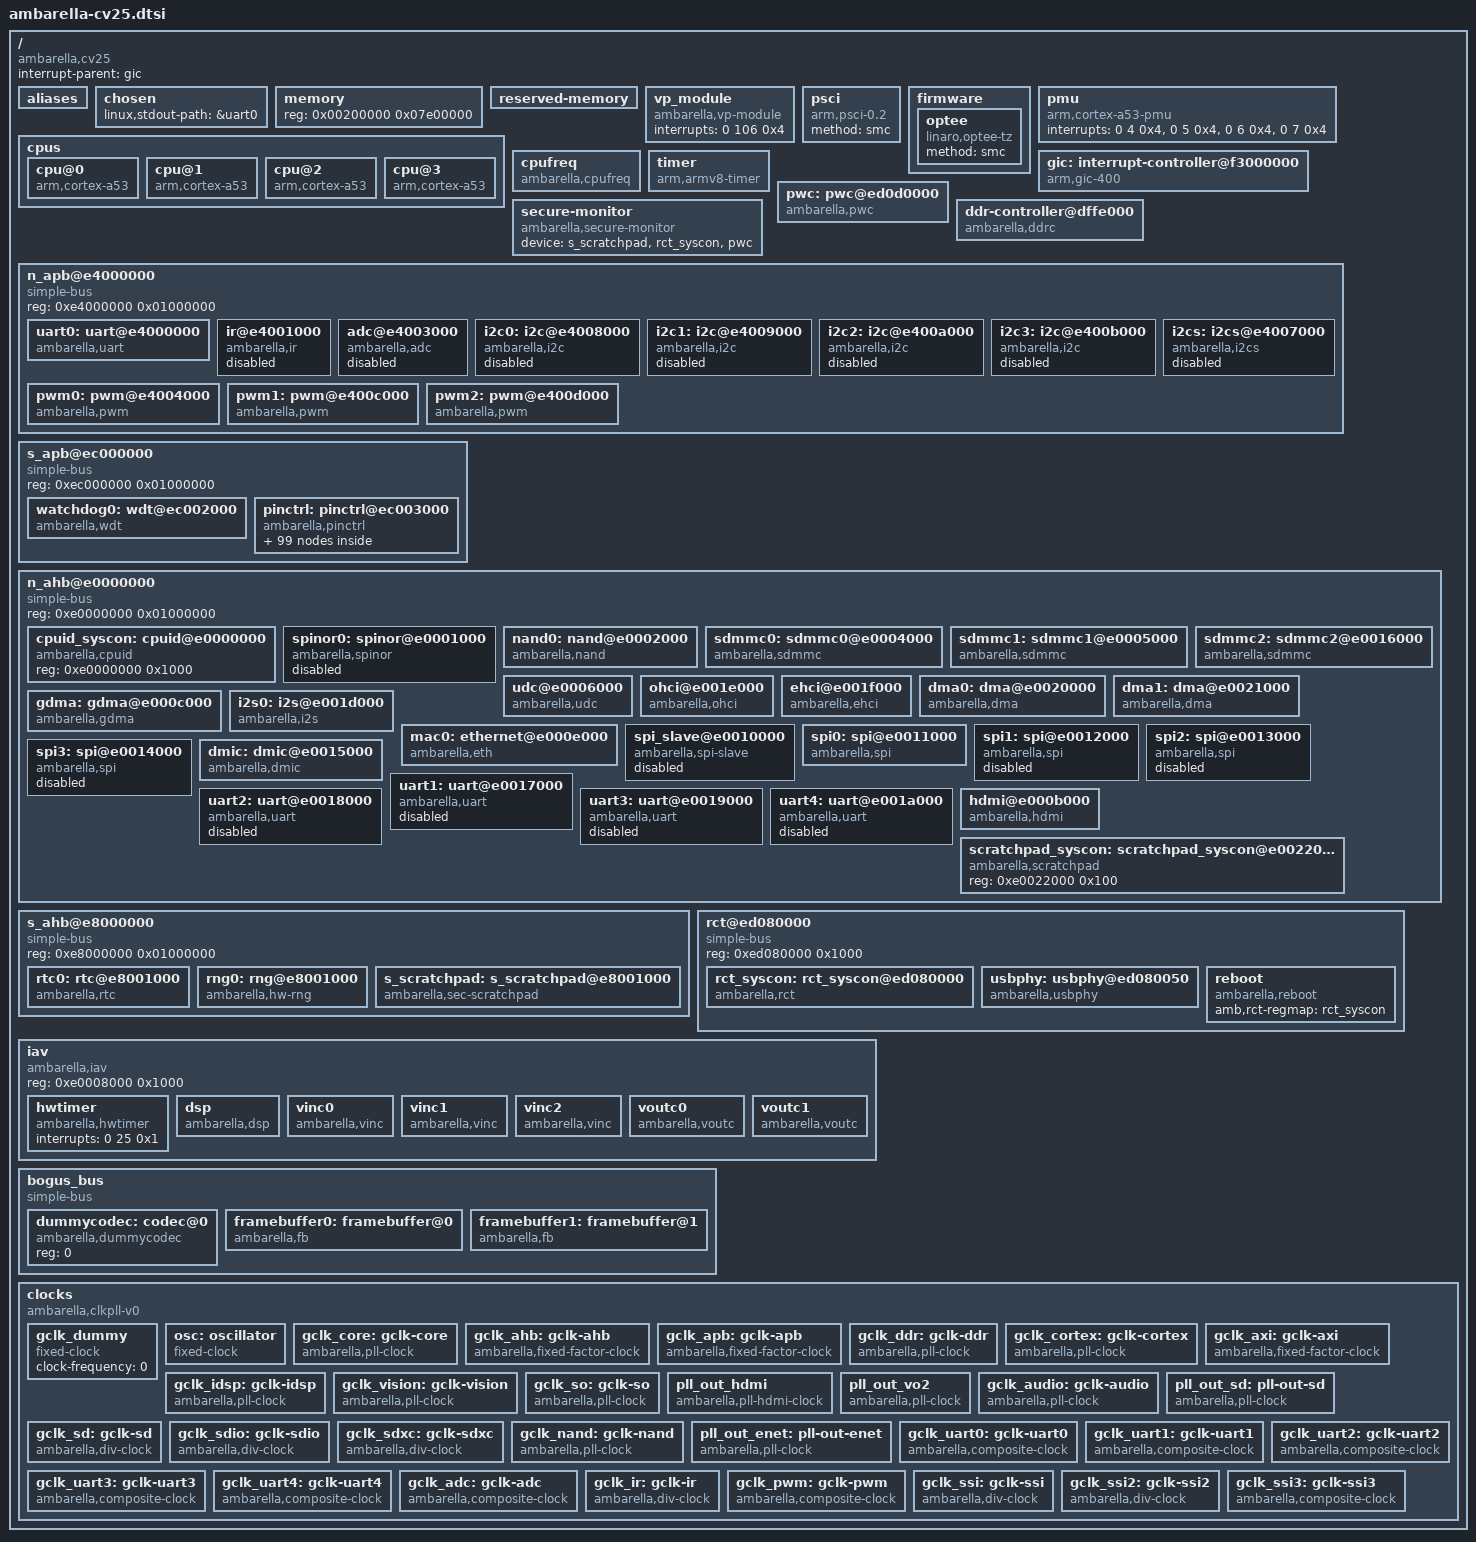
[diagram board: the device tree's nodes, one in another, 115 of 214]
/*
 * Copyright (C) 2013 Ambarella,Inc. - http://www.ambarella.com/
 * Author: Cao Rongrong <rrcao@ambarella.com>
 *
 * This program is free software; you can redistribute it and/or modify
 * it under the terms of the GNU General Public License version 2 as
 * published by the Free Software Foundation.
 */

/ {
	compatible = "ambarella,cv25";
	interrupt-parent = <&gic>;
	#address-cells = <1>;
	#size-cells = <1>;

	aliases {
		serial0 = &uart0;
		serial1 = &uart1;
		serial2 = &uart2;
		serial3 = &uart3;
		serial4 = &uart4;
		nand = &nand0;
		sd0 = &sdmmc0;
		sd1 = &sdmmc1;
		sd2 = &sdmmc2;
		spinor = &spinor0;
		i2c0 = &i2c0;
		i2c1 = &i2c1;
		i2c2 = &i2c2;
		i2c3 = &i2c3;
		i2c4 = &i2cs;
		spi0 = &spi0;
		spi1 = &spi1;
		spi2 = &spi2;
		spi3 = &spi3;
		ethernet0 = &mac0;
	};

	chosen {
		linux,stdout-path = &uart0;
	};

	/*
	 * the memory node will be overwritten in Amboot,
	 * here is just the default value.
	 */
	memory {
		device_type = "memory";
		reg = <0x00200000 0x07e00000>; /* 126M */
	};

	reserved-memory {
		#address-cells = <1>;
		#size-cells = <1>;
		ranges;
	};

	vp_module: vp_module {
		compatible = "ambarella,vp-module";
		interrupts = <0 106 0x4>;
	};

	psci {
		compatible = "arm,psci-0.2";
		method = "smc";
	};

	firmware {
		optee {
			compatible = "linaro,optee-tz";
			method = "smc";
		};
	};

	pmu {
		compatible = "arm,cortex-a53-pmu";
		interrupts = <0 4 0x4>,
			     <0 5 0x4>,
			     <0 6 0x4>,
			     <0 7 0x4>;
	};

	cpus {
		#address-cells = <1>;
		#size-cells = <0>;
		cpu@0 {
			compatible = "arm,cortex-a53", "arm,armv8";
			device_type = "cpu";
			reg = <0x0>;
			enable-method = "psci";
		};

		cpu@1 {
			compatible = "arm,cortex-a53", "arm,armv8";
			device_type = "cpu";
			reg = <0x1>;
			enable-method = "psci";
		};

		cpu@2 {
			compatible = "arm,cortex-a53", "arm,armv8";
			device_type = "cpu";
			reg = <0x2>;
			enable-method = "psci";
		};

		cpu@3 {
			compatible = "arm,cortex-a53", "arm,armv8";
			device_type = "cpu";
			reg = <0x3>;
			enable-method = "psci";
		};
	};

	cpufreq {
		compatible = "ambarella,cpufreq";
		/*
		 * Config effective clocks. '%KHZ'
		 *
		 * 0 - cortex.
		 * 1 - core.
		 * 2 - cortex and core.
		 */
		cpufreq-effective-clock = <0>;			/* default 'cortex' */
		clocks = <&gclk_cortex &gclk_core>;
		clock-names = "cortex_clk", "core_clk";
		clocks-frequency-cortex-core =
			<1008000  504000>,
			< 816000  336000>,
			< 600000  240000>;
	};

	gic: interrupt-controller@f3000000 {
		compatible = "arm,gic-400";
		#interrupt-cells = <3>;
		#address-cells = <0>;
		interrupt-controller;
		reg = <0xf3001000 0x1000>,	/* GIC Dist */
		      <0xf3002000 0x2000>,	/* GIC CPU */
		      /* following are not used if no virtulization */
		      <0xf3004000 0x2000>,	/* GIC VCPU Control */
		      <0xf3006000 0x2000>;	/* GIC VCPU */
		interrupts = <1 9 0xf04>;	/* GIC Maintenence IRQ */
	};

	timer {
		compatible = "arm,armv8-timer";
		interrupts = <1 13 0xf08>,	/* Secure Phys IRQ */
			     <1 14 0xf08>,	/* Non-secure Phys IRQ */
			     <1 11 0xf08>,	/* Virt IRQ */
			     <1 10 0xf08>;	/* Hyp IRQ */
	};

	pwc: pwc@ed0d0000 {
		status = "ok";
		compatible = "ambarella,pwc";
		reg = <0xed0d0000 0x1000>;
		amb,secure-ctrl-bit = <73>;
		amb,secure-addr-na = <0xed0d0000 0x40>;
	};

	secure-monitor {
		compatible = "ambarella,secure-monitor";
		#address-cells = <1>;
		#size-cells = <0>;
		device = <&s_scratchpad &rct_syscon &pwc>;
	};

	ddr-controller@dffe000 {
		compatible = "ambarella,ddrc";
		#address-cells = <1>;
		#size-cells = <0>;
		reg = <0xdffe0000 0x2000>;
		burst-size = <0>;		/* This property will be overwritten in AMBOOT. */
	};

	n_apb@e4000000 { /* Non-Secure APB, but configurable */
		compatible = "simple-bus";
		#address-cells = <1>;
		#size-cells = <1>;
		reg = <0xe4000000 0x01000000>;
		ranges;

		uart0: uart@e4000000 {
			compatible = "ambarella,uart";
			reg = <0xe4000000 0x1000>;
			interrupts = <0 21 0x4>;
			pinctrl-names = "default";
			pinctrl-0 = <&uart0_pins>;
			clocks = <&gclk_uart0>;
			amb,ignore-fe;
			status = "ok";
		};

		ir@e4001000 {
			compatible = "ambarella,ir";
			reg = <0xe4001000 0x1000>;
			interrupts = <0 20 0x4>;
			pinctrl-names = "default";
			pinctrl-0 = <&ir_pins>;
			clocks = <&gclk_ir>;
			status = "disabled";
		};

		adc@e4003000 {
			compatible = "ambarella,adc";
			#io-channel-cells = <1>;
			reg = <0xe4003000 0x1000>;
			interrupts = <0 13 0x4>;
			clock-frequency = <3000000>;
			clocks = <&gclk_adc>;
			amb,rct-regmap = <&rct_syscon 0x198 0x000 0x000>;
			amb,channel-num = <3>;	/* ch0 exists, but no pin out for ch0 */
			amb,scaler-1v8 = <0x01>;
			status = "disabled";
		};

		i2c0: i2c@e4008000 {
			compatible = "ambarella,i2c";
			#address-cells = <1>;
			#size-cells = <0>;
			reg = <0xe4008000 0x1000>;
			interrupts = <0 15 0x4>;
			pinctrl-names = "default";
			pinctrl-0 = <&i2c0_pins_a>;
			clocks = <&gclk_apb>;
			clock-frequency = <100000>;
			amb,i2c-class = <0x81>;
			status = "disabled";
		};

		i2c1: i2c@e4009000 {
			compatible = "ambarella,i2c";
			#address-cells = <1>;
			#size-cells = <0>;
			reg = <0xe4009000 0x1000>;
			interrupts = <0 16 0x4>;
			pinctrl-names = "default";
			pinctrl-0 = <&i2c1_pins_a>;
			clocks = <&gclk_apb>;
			clock-frequency = <100000>;
			amb,i2c-class = <0x08>;
			status = "disabled";
		};

		i2c2: i2c@e400a000 {
			compatible = "ambarella,i2c";
			#address-cells = <1>;
			#size-cells = <0>;
			reg = <0xe400a000 0x1000>;
			interrupts = <0 17 0x4>;
			clocks = <&gclk_apb>;
			pinctrl-names = "default";
			pinctrl-0 = <&i2c2_pins_a>;
			clock-frequency = <100000>;
			amb,i2c-class = <0x81>;
			status = "disabled";
		};

		i2c3: i2c@e400b000 {
			compatible = "ambarella,i2c";
			#address-cells = <1>;
			#size-cells = <0>;
			reg = <0xe400b000 0x1000>;
			interrupts = <0 18 0x4>;
			clocks = <&gclk_apb>;
			pinctrl-names = "default";
			pinctrl-0 = <&i2c3_pins>;
			clock-frequency = <100000>;
			amb,i2c-class = <0x81>;
			status = "disabled";
		};

		i2cs: i2cs@e4007000 {
			compatible = "ambarella,i2cs";
			#address-cells = <1>;
			#size-cells = <0>;
			reg = <0xe4007000 0x1000>;
			interrupts = <0 19 0x4>;
			clocks = <&gclk_apb>;
			pinctrl-names = "default";
			pinctrl-0 = <&i2cs0_pins>;
			status = "disabled";
		};

		pwm0: pwm@e4004000 {
			compatible = "ambarella,pwm";
			reg = <0xe4004000 0x1000>;
			clock-frequency = <2000000>;
			clocks = <&gclk_pwm>;
			#pwm-cells = <3>;
		};

		pwm1: pwm@e400c000 {
			compatible = "ambarella,pwm";
			reg = <0xe400c000 0x1000>;
			clock-frequency = <2000000>;
			clocks = <&gclk_pwm>;
			#pwm-cells = <3>;
		};

		pwm2: pwm@e400d000 {
			compatible = "ambarella,pwm";
			reg = <0xe400d000 0x1000>;
			clock-frequency = <2000000>;
			clocks = <&gclk_pwm>;
			#pwm-cells = <3>;
		};
	};

	s_apb@ec000000 { /* Secure APB, but configurable */
		compatible = "simple-bus";
		#address-cells = <1>;
		#size-cells = <1>;
		reg = <0xec000000 0x01000000>;
		ranges;

		watchdog0: wdt@ec002000 {
			compatible = "ambarella,wdt";
			reg = <0xec002000 0x1000>;
			amb,rct-regmap = <&rct_syscon>;
			/* interrupts = <0 42 0x4>; */
			timeout-sec = <15>;
			clocks = <&gclk_apb>;
			amb,secure-ctrl-bit = <49>;
		};

		pinctrl: pinctrl@ec003000 {
			compatible = "ambarella,pinctrl";
			#address-cells = <1>;
			#size-cells = <0>;
			reg = <0xec003000 0x1000>,
			      <0xec004000 0x1000>,
			      <0xec005000 0x1000>,
			      <0xec006000 0x1000>,
			      <0xec000000 0x1000>;
			reg-names = "gpio0", "gpio1", "gpio2", "gpio3", "iomux";
			interrupts = <0 43 0x4>,
				     <0 44 0x4>,
				     <0 45 0x4>,
				     <0 46 0x4>;
			amb,pull-regmap = <&scratchpad_syscon 0x14 0x30>;
			amb,ds-regmap = <&rct_syscon>;
			amb,secure-ctrl-bit = <50 51 52 53 48>;

			gpio: gpio@0 {
				reg = <0>;
				gpio-controller;
				#gpio-cells = <2>;
				gpio-ranges = <&pinctrl 0 0 108>;
				interrupt-controller;
				#interrupt-cells = <2>;
			};

			uart0_pins: uart0@0 {
				reg = <0>;
				amb,pinmux-ids = <0x1011 0x1012>;
			};

			uart1_pins: uart1@0 {
				reg = <0>;
				amb,pinmux-ids = <0x1057 0x1058>;
			};

			uart1_flow_pins: uart1_flow@0 {
				reg = <0>;
				amb,pinmux-ids = <0x1059 0x105a>;
			};

			uart2_pins: uart2@0 {
				reg = <0>;
				amb,pinmux-ids = <0x105b 0x105c>;
			};

			uart2_flow_pins: uart2_flow@0 {
				reg = <0>;
				amb,pinmux-ids = <0x105d 0x105e>;
			};

			uart3_pins_a: uart3@0 {
				reg = <0>;
				amb,pinmux-ids = <0x1048 0x1049>;
			};

			uart3_pins_b: uart3@1 {
				reg = <1>;
				amb,pinmux-ids = <0x4061 0x4062>;
			};

			uart3_flow_pins_a: uart3_flow@0 {
				reg = <0>;
				amb,pinmux-ids = <0x104a 0x104b>;
			};

			uart3_flow_pins_b: uart3_flow@1 {
				reg = <1>;
				amb,pinmux-ids = <0x4063 0x4064>;
			};

			uart4_pins_a: uart4@0 {
				reg = <0>;
				amb,pinmux-ids = <0x104c 0x104d>;
			};

			uart4_pins_b: uart4@1 {
				reg = <1>;
				amb,pinmux-ids = <0x4065 0x4066>;
			};

			uart4_flow_pins_a: uart4_flow@0 {
				reg = <0>;
				amb,pinmux-ids = <0x104e 0x104f>;
			};

			uart4_flow_pins_b: uart4_flow@1 {
				reg = <1>;
				amb,pinmux-ids = <0x4067 0x4068>;
			};

			nand0_pins: nand0@0 {
				reg = <0>;
				amb,pinmux-ids = <0x202d 0x202e 0x202f 0x2034
						  0x2035 0x2036 0x2037 0x2038
						  0x2039 0x203a 0x203b 0x203c
						  0x203d 0x203e 0x203f>;
			};

			snand0_pins: snand0@0 {
				reg = <0>;
				amb,pinmux-ids = <0x402d 0x4037 0x403b 0x403c
						  0x403d 0x403e>;
			};

			spinor0_pins: spinor0@0 {
				reg = <0>;
				amb,pinmux-ids = <0x302d 0x302f 0x3034 0x3035
						  0x3036 0x3037 0x3038 0x3039
						  0x303a 0x303b 0x303c 0x303d
						  0x303e>;
			};

			sdmmc0_cd_pin: sdmmc0_cd@0 {
				reg = <0>;
				amb,pinmux-ids = <0x2032>;
			};

			sdmmc0_wp_pin: sdmmc0_wp@0 {
				reg = <0>;
				amb,pinmux-ids = <0x2033>;
			};

			sdmmc0_reset_pin: sdmmc0_reset@0 {
				reg = <0>;
				amb,pinmux-ids = <0x2051>;
			};

			sdmmc0_pins_1bit: sdmmc0_1bit@0 {
				reg = <0>;
				amb,pinmux-ids = <0x2030 0x2031 0x2040>;
			};

			sdmmc0_pins_4bit: sdmmc0_4bit@0 {
				reg = <0>;
				amb,pinmux-ids = <0x2030 0x2031 0x2040 0x2041
						  0x2042 0x2043>;
			};

			sdmmc0_pins_8bit: sdmmc0_8bit@0 {
				reg = <0>;
				amb,pinmux-ids = <0x2030 0x2031 0x2040 0x2041
						  0x2042 0x2043 0x2044 0x2045
						  0x2046 0x2047>;
			};

			sdmmc1_cd_pin: sdmmc1_cd@0 {
				reg = <0>;
				amb,pinmux-ids = <0x204e>;
			};

			sdmmc1_wp_pin: sdmmc1_wp@0 {
				reg = <0>;
				amb,pinmux-ids = <0x204f>;
			};

			sdmmc1_reset_pin: sdmmc1_reset@0 {
				reg = <0>;
				amb,pinmux-ids = <0x2050>;
			};

			sdmmc1_pins_1bit: sdmmc1_1bit@0 {
				reg = <0>;
				amb,pinmux-ids = <0x2048 0x2049 0x204a>;
			};

			sdmmc1_pins_4bit: sdmmc1_4bit@0 {
				reg = <0>;
				amb,pinmux-ids = <0x2048 0x2049 0x204a 0x204b
						  0x204c 0x204d>;
			};

			sdmmc2_cd_pin: sdmmc2_cd@0 {
				reg = <0>;
				amb,pinmux-ids = <0x1067>;
			};

			sdmmc2_wp_pin: sdmmc2_wp@0 {
				reg = <0>;
				amb,pinmux-ids = <0x1068>;
			};

			sdmmc2_pins_1bit: sdmmc2_1bit@0 {
				reg = <0>;
				amb,pinmux-ids = <0x1065 0x1066 0x1061>;
			};

			sdmmc2_pins_4bit: sdmmc2_4bit@0 {
				reg = <0>;
				amb,pinmux-ids = <0x1065 0x1066 0x1061 0x1062
						  0x1063 0x1064>;
			};

			rgmii_pins: eth0@0 {
				reg = <0>;
				amb,pinmux-ids = <0x401c 0x401d 0x401e 0x401f
						  0x4020 0x4021 0x4022 0x4023
						  0x4024 0x4025 0x4029 0x402a
						  0x402b 0x5026 0x5027>;
			};

			rmii_pins: eth0@1 {
				reg = <1>;
				amb,pinmux-ids = <0x301c 0x301d 0x301e 0x3021
						  0x3022 0x3025 0x3029 0x302b
						  0x5026 0x5027>;
			};

			enet_ptp_pps_o_pins_a: enet_ptp_pps_o@0 {
				reg = <0>;
				amb,pinmux-ids = <0x4028>;
			};

			enet_ptp_pps_o_pins_b: enet_ptp_pps_o@1 {
				reg = <1>;
				amb,pinmux-ids = <0x3028>;
			};

			enet_2nd_ref_clk_pins_a: enet_2nd_ref_clk@0 {
				reg = <0>;
				amb,pinmux-ids = <0x302c>;
			};

			enet_2nd_ref_clk_pins_b: enet_2nd_ref_clk@1 {
				reg = <1>;
				amb,pinmux-ids = <0x302a>;
			};

			i2c0_pins_a: i2c0@0 {
				reg = <0>;
				amb,pinmux-ids = <0x3001 0x3002>;
			};

			i2c0_pins_b: i2c0@1 {
				reg = <1>;
				amb,pinmux-ids = <0x300f 0x3010>;
			};

			i2c0_pins_c: i2c0@2 {
				reg = <2>;
				amb,pinmux-ids = <0x304f 0x3050>;
			};

			i2c0_pins_d: i2c0@3 {
				reg = <3>;
				amb,pinmux-ids = <0x205f 0x2060>;
			};

			i2c1_pins_a: i2c1@0 {
				reg = <0>;
				amb,pinmux-ids = <0x2006 0x2007>;
			};

			i2c1_pins_b: i2c1@1 {
				reg = <1>;
				amb,pinmux-ids = <0x3065 0x3066>;
			};

			i2c2_pins_a: i2c2@0 {
				reg = <0>;
				amb,pinmux-ids = <0x2004 0x2008>;
			};

			i2c2_pins_b: i2c2@1 {
				reg = <1>;
				amb,pinmux-ids = <0x3067 0x3068>;
			};

			i2c3_pins: i2c3@0 {
				reg = <0>;
				amb,pinmux-ids = <0x200b 0x200c>;
			};

			i2cs0_pins: i2cs0@0 {
				reg = <0>;
				amb,pinmux-ids = <0x1001 0x1002>;
			};

			ir_pins: ir0@0 {
				reg = <0>;
				amb,pinmux-ids = <0x1003>;
			};

			wdt_pins_a: wdt0@0 {
				reg = <0>;
				amb,pinmux-ids = <0x2003>;
			};

			wdt_pins_b: wdt0@1 {
				reg = <1>;
				amb,pinmux-ids = <0x3008>;
			};

			wdt_pins_c: wdt0@2 {
				reg = <2>;
				amb,pinmux-ids = <0x2015>;
			};

			wdt_pins_d: wdt0@3 {
				reg = <3>;
				amb,pinmux-ids = <0x202c>;
			};

			wdt_pins_e: wdt0@4 {
				reg = <4>;
				amb,pinmux-ids = <0x2054>;
			};

			wdt_pins_f: wdt0@5 {
				reg = <5>;
				amb,pinmux-ids = <0x5066>;
			};

			i2s0_pins: i2s0@0 {
				reg = <0>;
				amb,pinmux-ids = <0x1016 0x1017 0x1018 0x101b>;
			};

			i2s0_ch2_pins: i2s0_ch2@0 {
				reg = <0>;
				amb,pinmux-ids = <0x1019 0x101a>;
			};

			dmic0_pins: dmic_pins@0 {
				reg = <0>;
				amb,pinmux-ids = <0x3014 0x3015>;
			};

			dmic1_pins: dmic_pins@1 {
				reg = <1>;
				amb,pinmux-ids = <0x3016 0x3017>;
			};

			dmic2_pins: dmic_pins@2 {
				reg = <2>;
				amb,pinmux-ids = <0x4019 0x401a>;
			};

			usb_host0_pins_a: uhc0@0 { /* USB0: host/device configurable */
				reg = <0>;
				amb,pinmux-ids = <0x3019 0x301a>;
			};

			usb_host0_pins_b: uhc0@1 { /* USB0: host/device configurable */
				reg = <1>;
				amb,pinmux-ids = <0x4011 0x4012>;
			};

			usb_host0_pins_c: uhc0@2 { /* USB0: host/device configurable */
				reg = <2>;
				amb,pinmux-ids = <0x3057 0x3059>;
			};

			usb_host0_pins_d: uhc0@3 { /* USB0: host/device configurable */
				reg = <3>;
				amb,pinmux-ids = <0x5061 0x5062>;
			};

			pwm0_pins_a: pwm0@0 {
				reg = <0>;
				amb,pinmux-ids = <0x1013>;
			};

			pwm0_pins_b: pwm0@1 {
				reg = <1>;
				amb,pinmux-ids = <0x2020>;
			};

			pwm0_pins_c: pwm0@2 {
				reg = <2>;
				amb,pinmux-ids = <0x102c>;
			};

			pwm1_pins: pwm1@0 {
				reg = <0>;
				amb,pinmux-ids = <0x1014>;
			};

			pwm2_pins: pwm2@0 {
				reg = <0>;
				amb,pinmux-ids = <0x1015>;
			};

			pwm3_pins_a: pwm3@0 {
				reg = <0>;
				amb,pinmux-ids = <0x3004>;
			};

			pwm3_pins_b: pwm3@1 {
				reg = <1>;
				amb,pinmux-ids = <0x2024>;
			};

			pwm4_pins_a: pwm4@0 {
				reg = <0>;
				amb,pinmux-ids = <0x3005>;
			};

			pwm4_pins_b: pwm4@1 {
				reg = <1>;
				amb,pinmux-ids = <0x2025>;
			};

			pwm5_pins_a: pwm5@0 {
				reg = <0>;
				amb,pinmux-ids = <0x3006>;
			};

			pwm5_pins_b: pwm5@1 {
				reg = <1>;
				amb,pinmux-ids = <0x2026>;
			};

			pwm6_pins_a: pwm6@0 {
				reg = <0>;
				amb,pinmux-ids = <0x3007>;
			};

			pwm6_pins_b: pwm6@1 {
				reg = <1>;
				amb,pinmux-ids = <0x2027>;
			};

			pwm7_pins_a: pwm7@0 {
				reg = <0>;
				amb,pinmux-ids = <0x3000>;
			};

			pwm7_pins_b: pwm7@1 {
				reg = <1>;
				amb,pinmux-ids = <0x2028>;
			};

			pwm7_pins_c: pwm7@2 {
				reg = <2>;
				amb,pinmux-ids = <0x5063>;
			};

			pwm8_pins_a: pwm8@0 {
				reg = <0>;
				amb,pinmux-ids = <0x201c>;
			};

			pwm8_pins_b: pwm8@1 {
				reg = <1>;
				amb,pinmux-ids = <0x2029>;
			};

			pwm8_pins_c: pwm8@2 {
				reg = <2>;
				amb,pinmux-ids = <0x5064>;
			};

			pwm9_pins_a: pwm9@0 {
				reg = <0>;
				amb,pinmux-ids = <0x201d>;
			};

			pwm9_pins_b: pwm9@1 {
				reg = <1>;
				amb,pinmux-ids = <0x202a>;
			};

			pwm9_pins_c: pwm9@2 {
				reg = <2>;
				amb,pinmux-ids = <0x5065>;
			};

			pwm10_pins: pwm10@0 {
				reg = <0>;
				amb,pinmux-ids = <0x201e>;
			};

			pwm11_pins: pwm11@0 {
				reg = <0>;
				amb,pinmux-ids = <0x201f>;
			};

			spi_slave_pins_a: spi_slave@0 {
				reg = <0>;
				amb,pinmux-ids = <0x200d 0x200e 0x200f 0x2010>;
			};

			spi_slave_pins_b: spi_slave@1 {
				reg = <1>;
				amb,pinmux-ids = <0x3061 0x3062 0x3063 0x3064>;
			};

			spi0_pins_a: spi0@0 {
				reg = <0>;
				amb,pinmux-ids = <0x1004 0x1005 0x1006>;
			};

			spi0_pins_b: spi0@1 {
				reg = <1>;
				amb,pinmux-ids = <0x2061 0x2062 0x2063>;
			};

			spi1_pins_a: spi1@0 {
				reg = <0>;
				amb,pinmux-ids = <0x2016 0x2017 0x2018>;
			};

			spi1_pins_b: spi1@1 {
				reg = <1>;
				amb,pinmux-ids = <0x3048 0x3049 0x304a>;
			};

			spi1_pins_c: spi1@2 {
				reg = <2>;
				amb,pinmux-ids = <0x2057 0x2058 0x2059>;
			};

			spi1_pins_d: spi1@3 {
				reg = <3>;
				amb,pinmux-ids = <0x2065 0x2066 0x2067>;
			};

			spi2_pins: spi2@0 {
				reg = <0>;
				amb,pinmux-ids = <0x1009 0x100a 0x100b>;
			};

			spi3_pins: spi3@0 {
				reg = <0>;
				amb,pinmux-ids = <0x100d 0x100e 0x100f>;
			};

			vout0_pins: vout0@0 {
				reg = <0>;
				amb,pinmux-ids = <0x101c 0x101d 0x101e 0x101f
						  0x1020 0x1021 0x1022 0x1023
						  0x1024 0x1025 0x1026 0x1027
						  0x1028 0x1029 0x102a 0x102b
						  0x305b 0x305c 0x305d 0x305e>;
				amb,pinconf-ids = <0xba001c 0xba001d 0xba001e 0xba001f
						   0xba0020 0xba0021 0xba0022 0xba0023
						   0xba0024 0xba0025 0xba0026 0xba0027
						   0xba0028 0xba0029 0xba002a 0xba002b
						   0xba005b 0xba005c 0xba005d 0xba005e>;
			};

		};
	};

	n_ahb@e0000000 { /* Non-Secure AHB, but configurable */
		compatible = "simple-bus";
		#address-cells = <1>;
		#size-cells = <1>;
		reg = <0xe0000000 0x01000000>;
		ranges;

		cpuid_syscon: cpuid@e0000000 {
			compatible = "ambarella,cpuid", "syscon";
			reg = <0xe0000000 0x1000>;
		};

		spinor0: spinor@e0001000 {
			compatible = "ambarella,spinor";
			reg = <0xe0001000 0x1000>; /* spi nor controller */
			interrupts = <0 73 0x4>;
			pinctrl-names = "default";
			pinctrl-0 = <&spinor0_pins>;
			clocks = <&gclk_ssi3>;
			dmas = <&dma0 5>, <&dma0 6>;
			dma-names = "tx", "rx";
			max-frequency = <50000000>;
			status = "disabled";
		};

		nand0: nand@e0002000 {
			compatible = "ambarella,nand";
			#address-cells = <1>;
			#size-cells = <1>;
			reg = <0xe0002000 0x1000>;
			interrupts = <0 68 0x4>;	/* fio_irq */
			amb,regmap = <&rct_syscon 0x074>;
			pinctrl-names = "default", "nand";
			pinctrl-0 = <&snand0_pins>;
			pinctrl-1 = <&nand0_pins>;
			clocks = <&gclk_nand>;
			nand-on-flash-bbt;
			/* amb,soft-ecc = <6>; */
		};

		sdmmc0: sdmmc0@e0004000 {
			compatible = "ambarella,sdmmc";
			#address-cells = <1>;
			#size-cells = <0>;
			reg = <0xe0004000 0x1000>;
			interrupts = <0 72 0x4>;
			pinctrl-names = "default";
			pinctrl-0 = <&sdmmc0_pins_8bit &sdmmc0_cd_pin &sdmmc0_wp_pin>;
			clocks = <&gclk_sd>;
			amb,rct-regmap = <&rct_syscon 0x4c0 0x4c4 0x664 0x4f0 0>;
			amb,tuning-tx-clk = <0>;
			amb,latctrl = <0x2>;
			max-frequency = <96000000>;
			bus-width = <8>;
			cap-sdio-irq;
			cap-sd-highspeed;
			cap-mmc-highspeed;
			mmc-hs200-1_8v;
		};

		sdmmc1: sdmmc1@e0005000 { /* SDIO0 */
			compatible = "ambarella,sdmmc";
			#address-cells = <1>;
			#size-cells = <0>;
			reg = <0xe0005000 0x1000>;
			interrupts = <0 71 0x4>;
			pinctrl-names = "default";
			pinctrl-0 = <&sdmmc1_pins_4bit &sdmmc1_cd_pin &sdmmc1_wp_pin>;
			clocks = <&gclk_sdxc>;
			amb,rct-regmap = <&rct_syscon 0x4c8 0x4cc 0x668 0x4f0 16>;
			amb,tuning-tx-clk = <0>;
			amb,latctrl = <0x2>;
			max-frequency = <96000000>;
			bus-width = <4>;
			cap-sdio-irq;
			cap-sd-highspeed;
			cap-mmc-highspeed;
		};

		sdmmc2: sdmmc2@e0016000 { /* SDIO1 */
			compatible = "ambarella,sdmmc";
			#address-cells = <1>;
			#size-cells = <0>;
			reg = <0xe0016000 0x1000>;
			interrupts = <0 64 0x4>;
			pinctrl-names = "default";
			pinctrl-0 = <&sdmmc2_pins_4bit &sdmmc2_cd_pin &sdmmc2_wp_pin>;
			clocks = <&gclk_sdio>;
			amb,latctrl = <0x2>;
			max-frequency = <48000000>;
			bus-width = <4>;
			cap-sdio-irq;
			cap-sd-highspeed;
			cap-mmc-highspeed;
		};

		udc@e0006000 {
			compatible = "ambarella,udc";
			reg = <0xe0006000 0x2000>;
			interrupts = <0 67 0x4>;
			amb,rct-regmap = <&rct_syscon>;
			amb,scr-regmap = <&scratchpad_syscon 0x94>;
			amb,usbphy = <&usbphy>;
		};

		ohci@e001e000 {
			compatible = "ambarella,ohci";
			reg = <0xe001e000 0x1000>;
			interrupts = <0 66 0x4>;
			amb,usbphy = <&usbphy>;
		};

		ehci@e001f000 {
			compatible = "ambarella,ehci";
			reg = <0xe001f000 0x1000>;
			interrupts = <0 65 0x4>;
			amb,usbphy = <&usbphy>;
		};

		dma0: dma@e0020000 {
			compatible = "ambarella,dma";
			reg = <0xe0020000 0x1000>;
			interrupts = <0 83 0x4>;
			#dma-cells = <1>;
			dma-channels = <8>;
			dma-requests = <23>;		/* request0 is reserved */
			amb,scr-regmap = <&scratchpad_syscon 0x50 0x54>;
		};

		dma1: dma@e0021000 {
			compatible = "ambarella,dma";
			reg = <0xe0021000 0x1000>;
			interrupts = <0 84 0x4>;
			#dma-cells = <1>;
			dma-channels = <8>;
			dma-requests = <23>;		/* request0 is reserved */
			amb,scr-regmap = <&scratchpad_syscon 0x58 0x5c>;
		};

		gdma: gdma@e000c000 {
			compatible = "ambarella,gdma";
			reg = <0xe000c000 0x400>;
			interrupts = <0 70 0x1>;
		};

		i2s0: i2s@e001d000 {
			compatible = "ambarella,i2s";
			#sound-dai-cells = <0>;
			reg = <0xe001d000 0x1000>;
			pinctrl-names = "default";
			pinctrl-0 = <&i2s0_pins>;
			clocks = <&gclk_audio>;
			amb,i2s-channels = <2>;
			amb,default-mclk = <12288000>;
			dmas = <&dma0 21>, <&dma0 22>;
			dma-names = "tx", "rx";
		};

		mac0: ethernet@e000e000 {
			compatible = "ambarella,eth";
			#address-cells = <1>;
			#size-cells = <0>;
			reg = <0xe000e000 0x2000>;
			interrupts = <0 58 0x4>;
			pinctrl-names = "default";
			pinctrl-0 = <&rgmii_pins>;
			phy-mode = "rgmii";
			amb,rct-regmap = <&rct_syscon>;
			amb,scr-regmap = <&scratchpad_syscon>;
			amb,tx-ring-size = <32>;
			amb,rx-ring-size = <64>;
			amb,ipc-tx;
			amb,ipc-rx;
			amb,ahb-12mhz-div = <5>;
			clock-names = "ptp_ref";
			clocks= <&osc>;
			/* amb,pps-avail; */
			/* amb,mdio-gpio; */
			/* amb,tx-clk-invert; */
		};

		spi_slave@e0010000 {
			compatible = "ambarella,spi-slave";
			reg = <0xe0010000 0x1000>;
			interrupts = <0 80 0x4>;
			pinctrl-names = "default";
			pinctrl-0 = <&spi_slave_pins_a>;
			clocks = <&gclk_ssi2>;
			dmas = <&dma1 7>, <&dma1 8>;
			dma-names = "tx", "rx";
			amb,dma-buf-size = <2048>;
			status = "disabled";
		};

		spi0: spi@e0011000 {
			compatible = "ambarella,spi";
			#address-cells = <1>;
			#size-cells = <0>;
			reg = <0xe0011000 0x1000>;
			interrupts = <0 74 0x4>;
			pinctrl-names = "default";
			pinctrl-0 = <&spi0_pins_a>;
			clocks = <&gclk_ssi>;
			/* amb,dma-used; */
			dmas = <&dma0 1>, <&dma0 2>;
			dma-names = "tx", "rx";
		};

		spi1: spi@e0012000 {
			compatible = "ambarella,spi";
			#address-cells = <1>;
			#size-cells = <0>;
			reg = <0xe0012000 0x1000>;
			interrupts = <0 75 0x4>;
			pinctrl-names = "default";
			pinctrl-0 = <&spi1_pins_b>;
			clocks = <&gclk_ssi>;
			/* amb,dma-used; */
			dmas = <&dma0 3>, <&dma0 4>;
			dma-names = "tx", "rx";
			status = "disabled";
		};

		spi2: spi@e0013000 {
			compatible = "ambarella,spi";
			#address-cells = <1>;
			#size-cells = <0>;
			reg = <0xe0013000 0x1000>;
			interrupts = <0 76 0x4>;
			pinctrl-names = "default";
			pinctrl-0 = <&spi2_pins>;
			clocks = <&gclk_ssi>;
			/* amb,dma-used; */
			dmas = <&dma1 17>, <&dma1 18>;
			dma-names = "tx", "rx";
			status = "disabled";
		};

		spi3: spi@e0014000 {
			compatible = "ambarella,spi";
			#address-cells = <1>;
			#size-cells = <0>;
			reg = <0xe0014000 0x1000>;
			interrupts = <0 77 0x4>;
			pinctrl-names = "default";
			pinctrl-0 = <&spi3_pins>;
			clocks = <&gclk_ssi>;
			/* amb,dma-used; */
			dmas = <&dma1 19>, <&dma1 20>;
			dma-names = "tx", "rx";
			status = "disabled";
		};

		dmic: dmic@e0015000 {
			compatible = "ambarella,dmic";
			reg = <0xe0015000 0x1000>;
			amb,scr-regmap = <&scratchpad_syscon>;
			#sound-dai-cells = <0>;
			amb,custom-iir;
		};

		uart1: uart@e0017000 {
			compatible = "ambarella,uart";
			reg = <0xe0017000 0x1000>;
			interrupts = <0 59 0x4>;
			pinctrl-names = "default";
			pinctrl-0 = <&uart1_pins &uart1_flow_pins>;
			clocks = <&gclk_uart1>;
			amb,msr-used;	/* use Modem Status Register */
			amb,ignore-fe;
			amb,txdma-used;
			amb,rxdma-used;
			dmas = <&dma0 9>, <&dma0 10>;
			dma-names = "tx", "rx";
			status = "disabled";
		};

		uart2: uart@e0018000 {
			compatible = "ambarella,uart";
			reg = <0xe0018000 0x1000>;
			interrupts = <0 60 0x4>;
			pinctrl-names = "default";
			pinctrl-0 = <&uart2_pins &uart2_flow_pins>;
			clocks = <&gclk_uart2>;
			amb,msr-used;	/* use Modem Status Register */
			amb,ignore-fe;
			amb,txdma-used;
			amb,rxdma-used;
			dmas = <&dma1 11>, <&dma1 12>;
			dma-names = "tx", "rx";
			status = "disabled";
		};

		uart3: uart@e0019000 {
			compatible = "ambarella,uart";
			reg = <0xe0019000 0x1000>;
			interrupts = <0 61 0x4>;
			pinctrl-names = "default";
			pinctrl-0 = <&uart3_pins_b &uart3_flow_pins_b>;
			clocks = <&gclk_uart3>;
			amb,msr-used;	/* use Modem Status Register */
			amb,ignore-fe;
			amb,txdma-used;
			amb,rxdma-used;
			dmas = <&dma1 13>, <&dma1 14>;
			dma-names = "tx", "rx";
			status = "disabled";
		};

		uart4: uart@e001a000 {
			compatible = "ambarella,uart";
			reg = <0xe001a000 0x1000>;
			interrupts = <0 62 0x4>;
			pinctrl-names = "default";
			pinctrl-0 = <&uart4_pins_a &uart4_flow_pins_a>;
			clocks = <&gclk_uart4>;
			amb,msr-used;	/* use Modem Status Register */
			amb,ignore-fe;
			amb,txdma-used;
			amb,rxdma-used;
			dmas = <&dma1 15>, <&dma1 16>;
			dma-names = "tx", "rx";
			status = "disabled";
		};

		hdmi@e000b000 {
			compatible = "ambarella,hdmi";
			reg = <0xe000b000 0x1000>;
			interrupts = <0 85 0x4>;
			interrupt-names = "hdmi";
			amb,hdmiphy = <0xed080010>;
			amb,hdmi-version = <20>;
			amb,phy-regmap = <&rct_syscon 0x10>;
			/* phy val : <pib pibib tap0_cur tap1_cur tap2_cur temination> */
			amb,hdmi-phy-val-version = <0>;
			amb,hdmi-phy-val-low = <0 2 8 1 1 3>;
			amb,hdmi-phy-val-high = <0 2 8 1 1 3>;
		};

		scratchpad_syscon: scratchpad_syscon@e0022000 {
			compatible = "ambarella,scratchpad", "syscon";
			reg = <0xe0022000 0x100>;
		};
	};

	s_ahb@e8000000 { /* Secure AHB, but configurable */
		compatible = "simple-bus";
		#address-cells = <1>;
		#size-cells = <1>;
		reg = <0xe8000000 0x01000000>;
		ranges;

		rtc0: rtc@e8001000 {
			compatible = "ambarella,rtc";
			reg = <0xe8001000 0x1000>;
			amb,secure-ctrl-bit = <31>;
		};

		rng0: rng@e8001000 {
			compatible = "ambarella,hw-rng";
			reg = <0xe8001000 0x14>;
			amb,rct-regmap = <&rct_syscon>;
			amb,secure-ctrl-bit = <31>;
		};

		s_scratchpad: s_scratchpad@e8001000 {
			compatible = "ambarella,sec-scratchpad";
			reg = <0xe8001000 0x1000>;
			amb,secure-ctrl-bit = <31>;
			amb,secure-addr-rw = <0xe8001000 0x1000>;
			amb,secure-addr-ro = <0xe80010a0 0x00c>, <0xe80010b4 0x004>;
		};
	};

	rct@ed080000 {
		compatible = "simple-bus";
		#address-cells = <1>;
		#size-cells = <1>;
		reg = <0xed080000 0x1000>;
		ranges;

		rct_syscon: rct_syscon@ed080000 {
			compatible = "ambarella,rct", "syscon";
			reg = <0xed080000 0x1000>;
			amb,secure-ctrl-bit = <68>;
			amb,secure-addr-rw = <0xed080000 0x1000>;
			amb,secure-addr-ro = <0xed080000 0x008>, <0xed080034 0x004>,
					    <0xed08008c 0x004>, <0xed0800dc 0x010>,
					    <0xed080100 0x01c>, <0xed080148 0x004>,
					    <0xed080174 0x00c>, <0xed0801f4 0x004>,
					    <0xed080220 0x00c>, <0xed080264 0x014>,
					    <0xed0802dc 0x010>, <0xed0803f8 0x008>,
					    <0xed0804f8 0x004>, <0xed0806e4 0x014>,
					    <0xed08070c 0x008>;
		};

		usbphy: usbphy@ed080050 {
			compatible = "ambarella,usbphy";
			reg = <0xed080050 0x4>,
				  <0xe0022060 0x4>,
				  <0xed0802c0 0x4>,
				  <0xed0802c4 0x4>,
				  <0xed0802c8 0x4>;
			amb,host-phy-num = <1>;
			amb,ocp-polarity = <0>;
		};

		reboot {
			compatible = "ambarella,reboot";
			amb,rct-regmap = <&rct_syscon>;
		};
	};

	iav {
		compatible = "ambarella,iav";
		#address-cells = <1>;
		#size-cells = <1>;
		reg-names = "vout_base";
		reg = <0xe0008000 0x1000>;
		ranges = <0x0 0xe0008000 0x1000>;

		hwtimer {
			compatible = "ambarella,hwtimer";
			interrupts = <0 25 0x1>;
			interrupt-names = "hwtimer";
		};

		/* node for dsp controller */
		dsp {
			compatible = "ambarella,dsp";
			interrupts = <0 141 0x1 0 142 0x1 0 143 0x1 0 144 0x1>;
			interrupt-names = "vdsp", "vapi", "venc", "vcap";
		};

		/* node for vin0 controller */
		vinc0 {
			compatible = "ambarella,vinc";
			interrupts = <0 110 0x1 0 111 0x1 0 112 0x1 0 140 0x1>;
			interrupt-names = "idsp", "idsp_sof", "idsp_last_pixel", "raw_cap";
			clocks = <&gclk_so>;
		};

		/* node for vin1 controller */
		vinc1 {
			compatible = "ambarella,vinc";
			interrupts = <0 135 0x1 0 136 0x1 0 137 0x1 0 147 0x1>;
			interrupt-names = "idsp", "idsp_sof", "idsp_last_pixel", "raw_cap";
			clocks = <&gclk_so>;
		};

		/* node for vin1 controller */
		vinc2 {
			compatible = "ambarella,vinc";
			interrupts = <0 114 0x1 0 115 0x1 0 116 0x1 0 148 0x1>;
			interrupt-names = "idsp", "idsp_sof", "idsp_last_pixel", "raw_cap";
			clocks = <&gclk_so>;
		};

		/* node for vout0(lcd) controller */
		voutc0 {
			compatible = "ambarella,voutc";
			output-type = "digital", "mipi_dsi", "fpd_link";
			reg-names = "display", "mipi_dsi_cmd";
			reg = <0x300 0x200>, <0xb00 0x18>;
			interrupts = <0 89 0x1>;
			interrupt-names = "vout0";
			rct-regmap = <&rct_syscon>;
			pinctrl-names = "default";
			pinctrl-0 = <&vout0_pins>;
			clocks = <&pll_out_vo2>;
		};

		/* node for vout1(tv) controller */
		voutc1 {
			compatible = "ambarella,voutc";
			output-type = "hdmi", "mipi_csi", "cvbs";
			reg-names = "display";
			reg = <0x600 0x200>;
			interrupts = <0 88 0x1>;
			interrupt-names = "vout1";
			rct-regmap = <&rct_syscon>;
			clocks = <&pll_out_hdmi>;
		};

	};

	bogus_bus {
		compatible = "simple-bus";
		#address-cells = <1>;
		#size-cells = <0>;

		dummycodec: codec@0 {
			compatible = "ambarella,dummycodec";
			reg = <0>;
		};

		framebuffer0: framebuffer@0 {
			compatible = "ambarella,fb";
			reg = <0>;
			amb,vout-id = <0>;
			amb,format = "rgb565";
		};

		framebuffer1: framebuffer@1 {
			compatible = "ambarella,fb";
			reg = <1>;
			amb,vout-id = <1>;
			amb,format = "rgb565";
		};
	};

	clocks {
		compatible = "ambarella,clkpll-v0";
		#address-cells = <1>;
		#size-cells = <1>;

		/*
		 * This is a dummy clock, to be used as placeholder on other
		 * mux clocks when corresponding bits in register don't
		 * represent real parent clock.
		 */
		gclk_dummy: gclk_dummy {
			#clock-cells = <0>;
			compatible = "fixed-clock";
			clock-frequency = <0>;
		};

		/*
		 * Fixed 24MHz oscillator inputs to SoC
		 */
		osc: oscillator {
			compatible = "fixed-clock";
			#clock-cells = <0>;
			clock-frequency = <24000000>;
			clock-output-names = "osc";
		};

		gclk_core: gclk-core {
			#clock-cells = <0>;
			compatible = "ambarella,pll-clock";
			clocks = <&osc>;
			clock-output-names = "gclk_core";
			amb,clk-regmap = <&rct_syscon 0x000 0x004 0x100 0x104 0x000 0x000>;
			amb,obsv-id = <0x00>;
		};

		gclk_ahb: gclk-ahb {
			#clock-cells = <0>;
			compatible = "ambarella,fixed-factor-clock";
			clocks = <&gclk_core>;
			clock-output-names = "gclk_ahb";
			clock-mult = <1>;
			clock-div = <2>;
		};

		gclk_apb: gclk-apb {
			#clock-cells = <0>;
			compatible = "ambarella,fixed-factor-clock";
			clocks = <&gclk_core>;
			clock-output-names = "gclk_apb";
			clock-mult = <1>;
			clock-div = <4>;
		};

		gclk_ddr: gclk-ddr {
			#clock-cells = <0>;
			compatible = "ambarella,pll-clock";
			clocks = <&osc>;
			clock-output-names = "gclk_ddr";
			amb,clk-regmap = <&rct_syscon 0x0dc 0x0e0 0x110 0x114 0x000 0x000>;
			amb,fix-divider = <2>;
			amb,obsv-id = <0x02>;
		};

		gclk_cortex: gclk-cortex {
			#clock-cells = <0>;
			compatible = "ambarella,pll-clock";
			clocks = <&osc>;
			clock-output-names = "gclk_cortex";
			amb,clk-regmap = <&rct_syscon 0x264 0x268 0x26c 0x270 0x000 0x000>;
			amb,obsv-id = <0x03>;
		};

		gclk_axi: gclk-axi {
			#clock-cells = <0>;
			compatible = "ambarella,fixed-factor-clock";
			clocks = <&gclk_cortex>;
			clock-output-names = "gclk_axi";
			clock-mult = <1>;
			clock-div = <3>;
		};

		gclk_idsp: gclk-idsp {
			#clock-cells = <0>;
			compatible = "ambarella,pll-clock";
			clocks = <&osc>;
			clock-output-names = "gclk_idsp";
			amb,clk-regmap = <&rct_syscon 0x0e4 0x0e8 0x108 0x10c 0x000 0x1f4>;
			amb,obsv-id = <0x01>;
		};

		gclk_vision: gclk-vision {
			#clock-cells = <0>;
			compatible = "ambarella,pll-clock";
			clocks = <&osc>;
			clock-output-names = "gclk_vision";
			amb,clk-regmap = <&rct_syscon 0x6e4 0x6e8 0x6ec 0x6f0 0x000 0x000>;
			amb,obsv-id = <0x04>;
		};

		gclk_so: gclk-so {
			#clock-cells = <0>;
			compatible = "ambarella,pll-clock";
			clocks = <&osc>;
			clock-output-names = "gclk_so";
			assigned-clocks = <&gclk_so>;
			assigned-clock-rates = <24000000>;
			amb,clk-regmap = <&rct_syscon 0x024 0x028 0x11c 0x120 0x04c 0x030>;
			amb,frac-mode;
			amb,obsv-id = <0x10>;
		};

		pll_out_hdmi: pll_out_hdmi {
			#clock-cells = <0>;
			compatible = "ambarella,pll-hdmi-clock";
			clocks = <&osc>;
			clock-output-names = "pll_out_hdmi";
			assigned-clocks = <&pll_out_hdmi>;
			assigned-clock-rates = <39000000>;
			amb,clk-regmap = <&rct_syscon 0x164 0x168 0x150 0x154 0x170 0x000>;
			amb,frac-mode;
			amb,ctrl2-val = <0x30520000>;
			amb,ctrl3-val = <0x00088004>;
			amb,obsv-id = <0x07>;
			amb,vco-min-mhz = <2496>;  /* in MHz */
			amb,vco-range = <0 2470 3200 4650 6800>;  /* in MHz */
		};

		pll_out_vo2: pll_out_vo2 {
			#clock-cells = <0>;
			compatible = "ambarella,pll-clock";
			clocks = <&osc>;
			clock-output-names = "pll_out_vo2";
			assigned-clocks = <&pll_out_vo2>;
			assigned-clock-rates = <24000000>;
			amb,clk-regmap = <&rct_syscon 0x0c0 0x0c4 0x13c 0x140 0x0c8 0x000>;
			amb,frac-mode;
			amb,vco-max-mhz = <1800>;
			amb,obsv-id = <0x09>;
		};

		gclk_audio: gclk-audio {
			#clock-cells = <0>;
			compatible = "ambarella,pll-clock";
			clocks = <&osc>;
			clock-output-names = "gclk_audio";
			assigned-clocks = <&gclk_audio>;
			assigned-clock-rates = <12288000>;
			amb,clk-regmap = <&rct_syscon 0x054 0x058 0x124 0x12c 0x060 0x05c>;
			amb,frac-mode;
			amb,obsv-id = <0x0b>;
		};

		pll_out_sd: pll-out-sd {
			#clock-cells = <0>;
			compatible = "ambarella,pll-clock";
			clocks = <&osc>;
			clock-output-names = "pll_out_sd";
			amb,clk-regmap = <&rct_syscon 0x4ac 0x4b0 0x4b4 0x4b8 0x000 0x000>;
			amb,obsv-id = <0x0c>;
		};

		gclk_sd: gclk-sd {
			#clock-cells = <0>;
			compatible = "ambarella,div-clock";
			clocks = <&pll_out_sd>;
			clock-output-names = "gclk_sd";
			amb,div-regmap = <&rct_syscon 0x00c>;
			amb,div-width = <16>;
			amb,div-shift = <0>;
		};

		gclk_sdio: gclk-sdio {
			#clock-cells = <0>;
			compatible = "ambarella,div-clock";
			clocks = <&pll_out_sd>;
			clock-output-names = "gclk_sdio";
			amb,div-regmap = <&rct_syscon 0x434>;
			amb,div-width = <16>;
			amb,div-shift = <0>;
		};

		gclk_sdxc: gclk-sdxc {
			#clock-cells = <0>;
			compatible = "ambarella,div-clock";
			clocks = <&pll_out_sd>;
			clock-output-names = "gclk_sdxc";
			amb,div-regmap = <&rct_syscon 0x430>;
			amb,div-width = <16>;
			amb,div-shift = <0>;
		};

		gclk_nand: gclk-nand {
			#clock-cells = <0>;
			compatible = "ambarella,pll-clock";
			clocks = <&osc>;
			clock-output-names = "gclk_nand";
			amb,clk-regmap = <&rct_syscon 0x6f8 0x6fc 0x700 0x704 0x000 0x000>;
			amb,obsv-id = <0x0e>;
		};

		pll_out_enet: pll-out-enet {
			#clock-cells = <0>;
			compatible = "ambarella,pll-clock";
			clocks = <&osc>;
			clock-output-names = "pll_out_enet";
			amb,clk-regmap = <&rct_syscon 0x520 0x524 0x528 0x52c 0x000 0x000>;
			amb,obsv-id = <0x0d>;
		};

		gclk_uart0: gclk-uart0 {
			#clock-cells = <0>;
			compatible = "ambarella,composite-clock";
			clocks = <&osc>, <&gclk_core>, <&pll_out_enet>, <&pll_out_sd>;
			clock-output-names = "gclk_uart0";
			assigned-clocks = <&gclk_uart0>;
			assigned-clock-parents = <&osc>;
			assigned-clock-rates = <24000000>;
			amb,mux-regmap = <&rct_syscon 0x1c8>;
			amb,div-regmap = <&rct_syscon 0x038>;
			amb,div-width = <24>;
			amb,div-shift = <0>;
		};

		gclk_uart1: gclk-uart1 {
			#clock-cells = <0>;
			compatible = "ambarella,composite-clock";
			clocks = <&osc>, <&gclk_core>, <&pll_out_enet>, <&pll_out_sd>;
			clock-output-names = "gclk_uart1";
			assigned-clocks = <&gclk_uart1>;
			assigned-clock-parents = <&osc>;
			assigned-clock-rates = <24000000>;
			amb,mux-regmap = <&rct_syscon 0x72c>;
			amb,div-regmap = <&rct_syscon 0x714>;
			amb,div-width = <24>;
			amb,div-shift = <0>;
		};

		gclk_uart2: gclk-uart2 {
			#clock-cells = <0>;
			compatible = "ambarella,composite-clock";
			clocks = <&osc>, <&gclk_core>, <&pll_out_enet>, <&pll_out_sd>;
			clock-output-names = "gclk_uart2";
			assigned-clocks = <&gclk_uart2>;
			assigned-clock-parents = <&osc>;
			assigned-clock-rates = <24000000>;
			amb,mux-regmap = <&rct_syscon 0x730>;
			amb,div-regmap = <&rct_syscon 0x718>;
			amb,div-width = <24>;
			amb,div-shift = <0>;
		};

		gclk_uart3: gclk-uart3 {
			#clock-cells = <0>;
			compatible = "ambarella,composite-clock";
			clocks = <&osc>, <&gclk_core>, <&pll_out_enet>, <&pll_out_sd>;
			clock-output-names = "gclk_uart3";
			assigned-clocks = <&gclk_uart3>;
			assigned-clock-parents = <&osc>;
			assigned-clock-rates = <24000000>;
			amb,mux-regmap = <&rct_syscon 0x734>;
			amb,div-regmap = <&rct_syscon 0x71c>;
			amb,div-width = <24>;
			amb,div-shift = <0>;
		};

		gclk_uart4: gclk-uart4 {
			#clock-cells = <0>;
			compatible = "ambarella,composite-clock";
			clocks = <&osc>, <&gclk_core>, <&pll_out_enet>, <&pll_out_sd>;
			clock-output-names = "gclk_uart4";
			assigned-clocks = <&gclk_uart4>;
			assigned-clock-parents = <&osc>;
			assigned-clock-rates = <24000000>;
			amb,mux-regmap = <&rct_syscon 0x738>;
			amb,div-regmap = <&rct_syscon 0x720>;
			amb,div-width = <24>;
			amb,div-shift = <0>;
		};

		gclk_adc: gclk-adc {
			#clock-cells = <0>;
			compatible = "ambarella,composite-clock";
			clocks = <&osc>, <&gclk_vision>, <&gclk_nand>;
			clock-output-names = "gclk_adc";
			amb,mux-regmap = <&rct_syscon 0x1d0>;
			amb,div-regmap = <&rct_syscon 0x09c>;
			amb,div-width = <16>;
			amb,div-shift = <0>;
			amb,fix-divider = <2>;
		};

		gclk_ir: gclk-ir {
			#clock-cells = <0>;
			compatible = "ambarella,div-clock";
			clocks = <&osc>;
			clock-output-names = "gclk_ir";
			amb,div-regmap = <&rct_syscon 0x044>;
			amb,div-width = <24>;
			amb,div-shift = <0>;
		};

		gclk_pwm: gclk-pwm {
			#clock-cells = <0>;
			compatible = "ambarella,composite-clock";
			clocks = <&gclk_apb>, <&gclk_cortex>, <&pll_out_enet>, <&osc>;
			clock-output-names = "gclk_pwm";
			assigned-clocks = <&gclk_pwm>;
			assigned-clock-parents = <&pll_out_enet>;
			amb,mux-regmap = <&rct_syscon 0x1c4>;
			amb,div-regmap = <&rct_syscon 0x084>;
			amb,div-width = <24>;
			amb,div-shift = <0>;
		};

		gclk_ssi: gclk-ssi { /* for SSI master */
			#clock-cells = <0>;
			compatible = "ambarella,div-clock";
			clocks = <&gclk_core>;
			clock-output-names = "gclk_ssi";
			assigned-clocks = <&gclk_ssi>;
			assigned-clock-rates = <54000000>;
			amb,div-regmap = <&rct_syscon 0x03c>;
			amb,div-width = <24>;
			amb,div-shift = <0>;
		};

		gclk_ssi2: gclk-ssi2 { /* for SSI slave */
			#clock-cells = <0>;
			compatible = "ambarella,div-clock";
			clocks = <&gclk_core>;
			clock-output-names = "gclk_ssi2";
			amb,div-regmap = <&rct_syscon 0x0ec>;
			amb,div-width = <24>;
			amb,div-shift = <0>;
		};

		gclk_ssi3: gclk-ssi3 { /* for SPINOR */
			#clock-cells = <0>;
			compatible = "ambarella,composite-clock";
			clocks = <&pll_out_enet>, <&gclk_core>, <&gclk_ssi>, <&osc>;
			clock-output-names = "gclk_ssi3";
			amb,mux-regmap = <&rct_syscon 0x51c>;
			amb,div-regmap = <&rct_syscon 0x518>;
			amb,div-width = <24>;
			amb,div-shift = <0>;
		};
	};
};
